# PY32F002Axx register map
Vendor: Puya; Series: PY32F0; File version: 1.0.0
CPU: CM0+ r0p1, little endian, no MPU, no FPU, 4 interrupt priority bits
Registers are 32-bit, read-write, reset 0x0 unless marked. A register's access mark holds for its fields unless they carry their own. Offsets are from the block's base; [hi:lo] are bit positions; {n}, {i} and the like mark numbered series.

## COMP1 — Comparator
Base 0x40010200
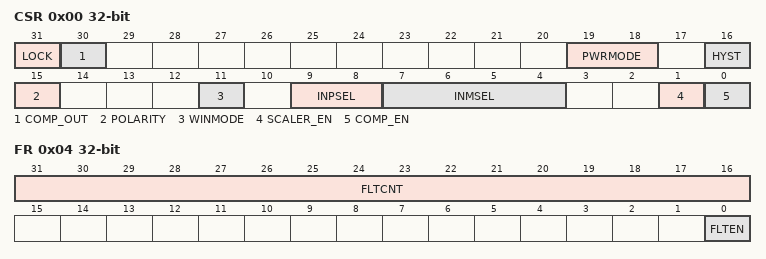
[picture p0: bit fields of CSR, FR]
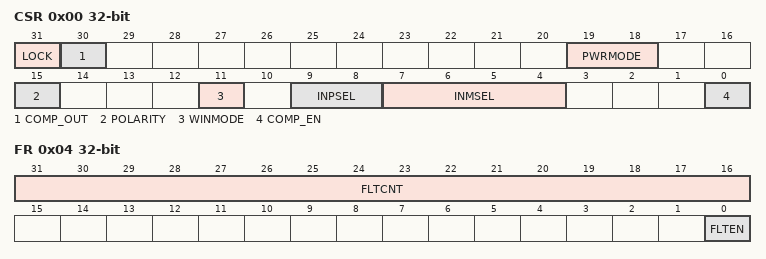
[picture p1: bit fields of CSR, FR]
0x00 CSR — COMP control and status register
  [31] LOCK — CSR register lock
  [30] COMP_OUT — Comparator output status
  [19:18] PWRMODE — Comparator power modeselector
    1=0; 2=1
  [16] HYST — Comparator hysteresis enableselector
  [15] POLARITY — Comparator polarityselector
  [11] WINMODE — Comparator non-inverting inputselector for window mode
  [9:8] INPSEL — Comparator signal selector fornon-inverting input
    1=0; 2=1
  [7:4] INMSEL — Comparator signal selector forinverting input INM
    1=0; 2=1; 4=2; 8=3
  [1] SCALER_EN — SCALER enable bit
  [0] COMP_EN — COMP enable bit
0x04 FR — Comparator Filterregister
  [31:16] FLTCNT — Comparator filter and counter
  [0] FLTEN — Filter enable bit

## COMP2 — Comparator
Base 0x40010210
0x00 CSR — COMP control and status register
  [31] LOCK — CSR register lock
  [30] COMP_OUT — Comparator output status
  [19:18] PWRMODE — Comparator power modeselector
    1=0; 2=1
  [15] POLARITY — Comparator polarityselector
  [11] WINMODE — Comparator non-inverting inputselector for window mode
  [9:8] INPSEL — Comparator signal selector fornon-inverting input
    1=0; 2=1
  [7:4] INMSEL — Comparator signal selector forinverting input INM
    1=0; 2=1; 4=2; 8=3
  [0] COMP_EN — COMP enable bit
0x04 FR — Comparator Filterregister
  [31:16] FLTCNT — Comparator filter and counter
  [0] FLTEN — Filter enable bit

## CRC — CRC calculation unit
Base 0x40023000
0x00 DR reset 0xFFFFFFFF — Data register
  [31:0] DR — Data Register
0x04 IDR — Independent Data register
  [7:0] IDR
0x08 CR wo — Control register
  [0] RESET — Reset bit

## DBGMCU — Debug support
Base 0x40015800
0x00 IDCODE ro — MCU Device ID Code Register
0x04 CR — Debug MCU Configuration Register
  [1] DBG_STOP — Debug Stop Mode
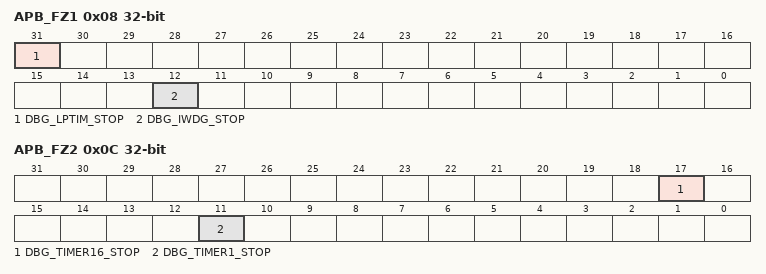
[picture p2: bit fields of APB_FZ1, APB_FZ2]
0x08 APB_FZ1 — APB Freeze Register1
  [31] DBG_LPTIM_STOP — Debug LPTIM stopped when Core is halted
  [12] DBG_IWDG_STOP — Debug Independent Wachdog stopped when Core is halted
0x0C APB_FZ2 — APB Freeze Register2
  [17] DBG_TIMER16_STOP — Debug Timer 16 stopped when Core is halted
  [11] DBG_TIMER1_STOP — Debug Timer 1 stopped when Core is halted

## EXTI — External interrupt/eventcontroller
Base 0x40021800
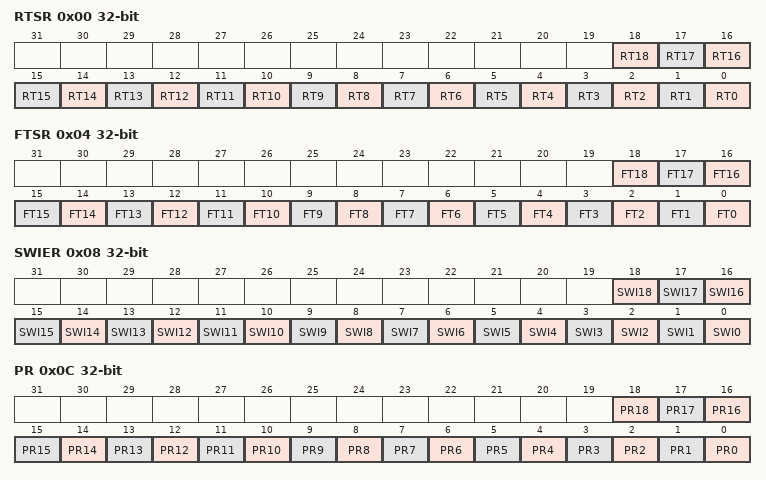
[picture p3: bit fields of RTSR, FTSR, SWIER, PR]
0x00 RTSR — EXTI rising trigger selectionregister
  [n] RT{n} (n=0..18) — Rising trigger event configuration bitof Configurable Event input
0x04 FTSR — EXTI falling trigger selectionregister
  [n] FT{n} (n=0..18) — Falling trigger event configuration bitof Configurable Event input
0x08 SWIER — EXTI software interrupt eventregister
  [n] SWI{n} (n=0..18) — Rising trigger event configuration bitof Configurable Event input
0x0C PR — EXTI pendingregister
  [n] PR{n} (n=14..18) — configurable event inputs x rising edgePending bit.
  [13] PR13 — configurable event inputs x rising edgePending bit
  [n] PR{n} (n=0..12) — configurable event inputs x rising edgePending bit.
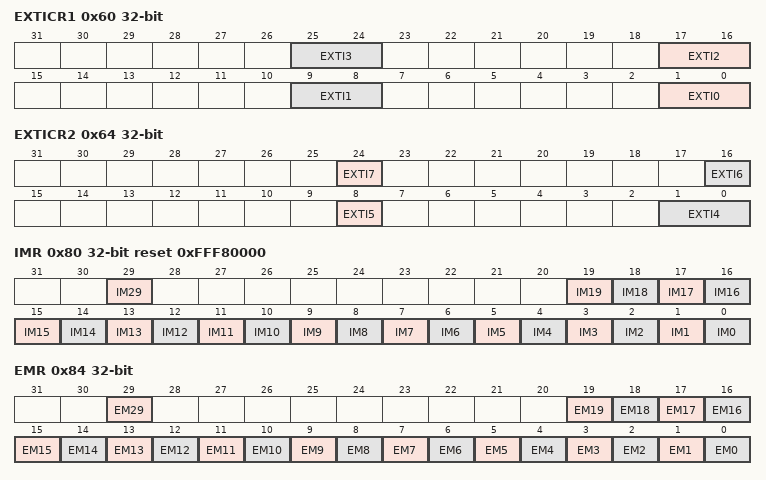
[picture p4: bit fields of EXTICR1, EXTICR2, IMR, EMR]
0x60 EXTICR1 — EXTI external interrupt selectionregister
  [all] fields
    1=0; 2=1
  [8n+1:8n] EXTI{n} (n=0..3) — GPIO port selection
0x64 EXTICR2 — EXTI external interrupt selectionregister
  [24] EXTI7 — GPIO port selection
  [16] EXTI6 — GPIO port selection
  [8] EXTI5 — GPIO port selection
  [1:0] EXTI4 — GPIO port selection
    1=0; 2=1
0x68 EXTICR3 — EXTI external interrupt selectionregister
  [0] EXTI8 — GPIO port selection
0x80 IMR reset 0xFFF80000 — EXTI CPU wakeup with interrupt maskregister
  [29] IM29 — CPU wakeup with interrupt mask on eventinput
  [n] IM{n} (n=0..19) — CPU wakeup with interrupt mask on eventinput
0x84 EMR — EXTI CPU wakeup with event maskregister
  [29] EM29 — CPU wakeup with event mask on eventinput
  [n] EM{n} (n=0..19) — CPU wakeup with event mask on eventinput
